BO_ 432 STANDSTILL: 7 VSA
 SG_ WHEELS_MOVING : 12|1@0+ (1,0) [0|1] "" EON

BO_ 342 STEERING_SENSORS: 6 EPS
 SG_ STEER_ANGLE_COURSE : 0|8@0- (1,0) [-128|127] "" EON
 SG_ STEER_ANGLE : 7|16@0- (-0.1,0) [-470|470] "deg" EON
 SG_ STEER_ANGLE_RATE : 23|16@0- (-1,0) [-3000|3000] "deg/s" EON

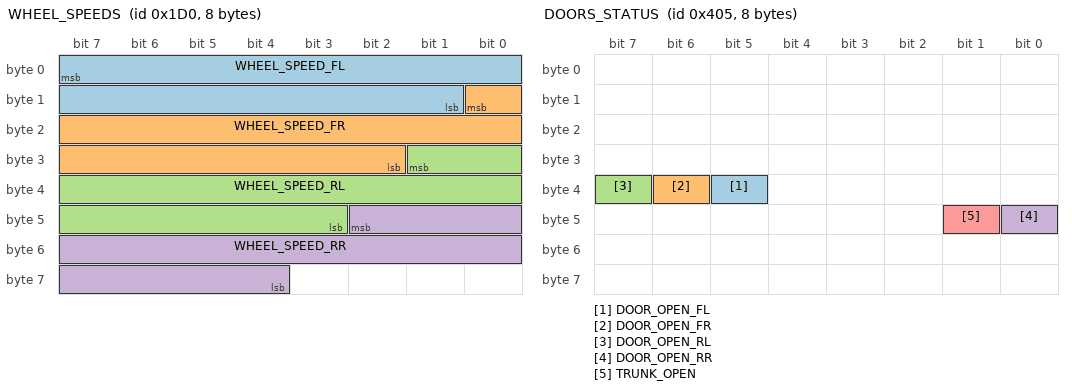
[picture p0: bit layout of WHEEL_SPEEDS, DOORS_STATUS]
BO_ 464 WHEEL_SPEEDS: 8 VSA
 SG_ WHEEL_SPEED_FL : 7|15@0+ (0.01,0) [0|250] "kph" EON
 SG_ WHEEL_SPEED_FR : 8|15@0+ (0.01,0) [0|250] "kph" EON
 SG_ WHEEL_SPEED_RL : 25|15@0+ (0.01,0) [0|250] "kph" EON
 SG_ WHEEL_SPEED_RR : 42|15@0+ (0.01,0) [0|250] "kph" EON

BO_ 490 VEHICLE_DYNAMICS: 8 VSA
 SG_ LAT_ACCEL : 7|16@0- (0.0015,0) [-20|20] "m/s2" EON
 SG_ LONG_ACCEL : 23|16@0- (0.0015,0) [-20|20] "m/s2" EON

BO_ 1029 DOORS_STATUS: 8 BDY
 SG_ DOOR_OPEN_FL : 37|1@0+ (1,0) [0|1] "" EON
 SG_ DOOR_OPEN_FR : 38|1@0+ (1,0) [0|1] "" EON
 SG_ DOOR_OPEN_RL : 39|1@0+ (1,0) [0|1] "" EON
 SG_ DOOR_OPEN_RR : 40|1@0+ (1,0) [0|1] "" EON
 SG_ TRUNK_OPEN : 41|1@0+ (1,0) [0|1] "" EON

BO_ 342 STEERING_SENSORS: 6 EPS
 SG_ STEER_ANGLE_COURSE : 0|8@0- (1,0) [-128|127] "" EON
 SG_ STEER_ANGLE : 7|16@0- (-0.1,0) [-470|470] "deg" EON
 SG_ STEER_ANGLE_RATE : 23|16@0- (-1,0) [-3000|3000] "deg/s" EON

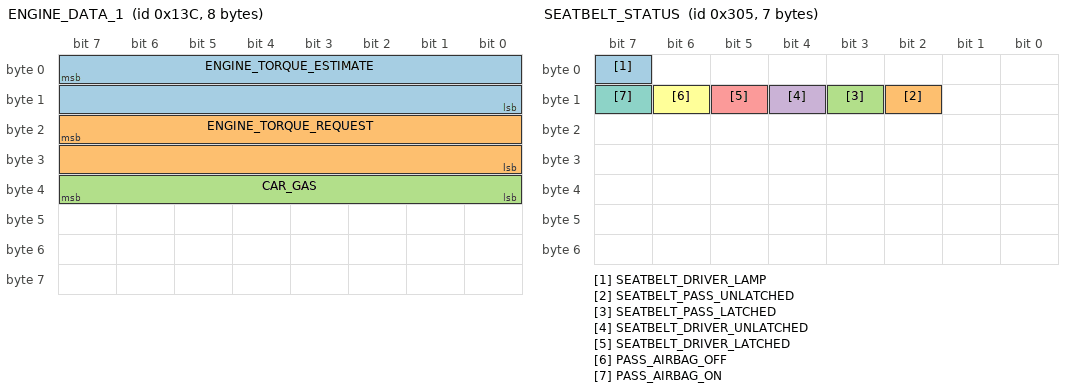
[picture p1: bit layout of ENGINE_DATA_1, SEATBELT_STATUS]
BO_ 316 ENGINE_DATA_1: 8 PCM
 SG_ ENGINE_TORQUE_ESTIMATE : 7|16@0- (1,0) [-1000|1000] "Nm" EON
 SG_ ENGINE_TORQUE_REQUEST : 23|16@0- (1,0) [-1000|1000] "Nm" EON
 SG_ CAR_GAS : 39|8@0+ (1,0) [0|255] "" EON

BO_ 773 SEATBELT_STATUS: 7 BDY
 SG_ SEATBELT_DRIVER_LAMP : 7|1@0+ (1,0) [0|1] "" EON
 SG_ SEATBELT_PASS_UNLATCHED : 10|1@0+ (1,0) [0|1] "" EON
 SG_ SEATBELT_PASS_LATCHED : 11|1@0+ (1,0) [0|1] "" EON
 SG_ SEATBELT_DRIVER_UNLATCHED : 12|1@0+ (1,0) [0|1] "" EON
 SG_ SEATBELT_DRIVER_LATCHED : 13|1@0+ (1,0) [0|1] "" EON
 SG_ PASS_AIRBAG_OFF : 14|1@0+ (1,0) [0|1] "" EON
 SG_ PASS_AIRBAG_ON : 15|1@0+ (1,0) [0|1] "" EON
